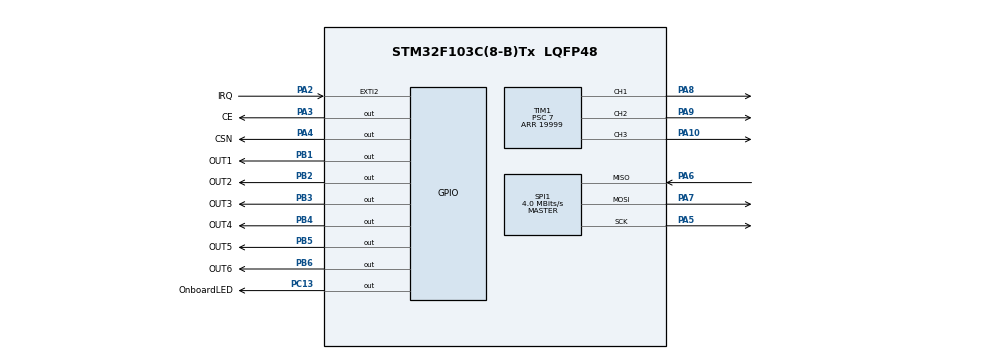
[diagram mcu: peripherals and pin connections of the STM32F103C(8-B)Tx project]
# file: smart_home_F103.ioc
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Mcu.Family=STM32F1
Mcu.Name=STM32F103C(8-B)Tx
Mcu.Package=LQFP48
NVIC.PriorityGroup=NVIC_PRIORITYGROUP_4
PA10.Signal=S_TIM1_CH3
PA13.Mode=Serial_Wire
PA13.Signal=SYS_JTMS-SWDIO
PA14.Mode=Serial_Wire
PA14.Signal=SYS_JTCK-SWCLK
PA2.GPIO_Label=IRQ
PA2.GPIO_ModeDefaultEXTI=GPIO_MODE_IT_FALLING
PA2.Signal=GPXTI2
PA3.GPIO_Label=CE
PA3.Signal=GPIO_Output
PA4.GPIO_Label=CSN
PA4.Signal=GPIO_Output
PA5.Mode=Full_Duplex_Master
PA5.Signal=SPI1_SCK
PA6.Mode=Full_Duplex_Master
PA6.Signal=SPI1_MISO
PA7.Mode=Full_Duplex_Master
PA7.Signal=SPI1_MOSI
PA8.Signal=S_TIM1_CH1
PA9.Signal=S_TIM1_CH2
PB1.GPIO_Label=OUT1
PB1.Signal=GPIO_Output
PB2.GPIO_Label=OUT2
PB2.Signal=GPIO_Output
PB3.GPIO_Label=OUT3
PB3.Signal=GPIO_Output
PB4.GPIO_Label=OUT4
PB4.Signal=GPIO_Output
PB5.GPIO_Label=OUT5
PB5.Signal=GPIO_Output
PB6.GPIO_Label=OUT6
PB6.Signal=GPIO_Output
PC13-TAMPER-RTC.GPIO_Label=OnboardLED
PC13-TAMPER-RTC.Signal=GPIO_Output
ProjectManager.HeapSize=0x200
ProjectManager.StackSize=0x400
ProjectManager.TargetToolchain=STM32CubeIDE
RCC.APB1Freq_Value=8000000
RCC.APB2Freq_Value=8000000
SH.S_TIM1_CH1.0=TIM1_CH1,PWM Generation1 CH1
SH.S_TIM1_CH2.0=TIM1_CH2,PWM Generation2 CH2
SH.S_TIM1_CH3.0=TIM1_CH3,PWM Generation3 CH3
SPI1.CalculateBaudRate=4.0 MBits/s
SPI1.Direction=SPI_DIRECTION_2LINES
SPI1.Mode=SPI_MODE_MASTER
SPI1.VirtualType=VM_MASTER
TIM1.Channel-PWM\ Generation1\ CH1=TIM_CHANNEL_1
TIM1.Channel-PWM\ Generation2\ CH2=TIM_CHANNEL_2
TIM1.Channel-PWM\ Generation3\ CH3=TIM_CHANNEL_3
TIM1.Period=19999
TIM1.Prescaler=7
TIM1.Pulse-PWM\ Generation1\ CH1=1540
TIM1.Pulse-PWM\ Generation2\ CH2=1540
TIM1.Pulse-PWM\ Generation3\ CH3=1540
board=custom

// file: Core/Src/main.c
/* USER CODE BEGIN Header */
/**
  ******************************************************************************
  * @file           : main.c
  * @brief          : Main program body
  ******************************************************************************
  * @attention
  *
  * <h2><center>&copy; Copyright (c) 2021 STMicroelectronics.
  * All rights reserved.</center></h2>
  *
  * This software component is licensed by ST under BSD 3-Clause license,
  * the "License"; You may not use this file except in compliance with the
  * License. You may obtain a copy of the License at:
  *                        opensource.org/licenses/BSD-3-Clause
  *
  ******************************************************************************
  */
/* USER CODE END Header */
#include "main.h"

/* USER CODE BEGIN Includes */
#include <client.h>
/* USER CODE END Includes */

SPI_HandleTypeDef hspi1;

TIM_HandleTypeDef htim1;

void SystemClock_Config(void);
static void MX_GPIO_Init(void);
static void MX_SPI1_Init(void);
static void MX_TIM1_Init(void);

int main(void)
{

  /* MCU Configuration--------------------------------------------------------*/

  /* Reset of all peripherals, Initializes the Flash interface and the Systick. */
  HAL_Init();

  /* Configure the system clock */
  SystemClock_Config();

  /* Initialize all configured peripherals */
  MX_GPIO_Init();
  MX_SPI1_Init();
  MX_TIM1_Init();
  /* USER CODE BEGIN 2 */
  smartHomeGPIOSwitcher(
      &htim1, TIM_CHANNEL_1,
      &htim1, TIM_CHANNEL_2,
      &htim1, TIM_CHANNEL_3
  );
  /* USER CODE END 2 */

  /* Infinite loop */
  while (1)
  {

  }
}

void SystemClock_Config(void)
{
  RCC_OscInitTypeDef RCC_OscInitStruct = {0};
  RCC_ClkInitTypeDef RCC_ClkInitStruct = {0};

  /** Initializes the RCC Oscillators according to the specified parameters
  * in the RCC_OscInitTypeDef structure.
  */
  RCC_OscInitStruct.OscillatorType = RCC_OSCILLATORTYPE_HSI;
  RCC_OscInitStruct.HSIState = RCC_HSI_ON;
  RCC_OscInitStruct.HSICalibrationValue = RCC_HSICALIBRATION_DEFAULT;
  RCC_OscInitStruct.PLL.PLLState = RCC_PLL_NONE;
  if (HAL_RCC_OscConfig(&RCC_OscInitStruct) != HAL_OK)
  {
    Error_Handler();
  }
  /** Initializes the CPU, AHB and APB buses clocks
  */
  RCC_ClkInitStruct.ClockType = RCC_CLOCKTYPE_HCLK|RCC_CLOCKTYPE_SYSCLK
                              |RCC_CLOCKTYPE_PCLK1|RCC_CLOCKTYPE_PCLK2;
  RCC_ClkInitStruct.SYSCLKSource = RCC_SYSCLKSOURCE_HSI;
  RCC_ClkInitStruct.AHBCLKDivider = RCC_SYSCLK_DIV1;
  RCC_ClkInitStruct.APB1CLKDivider = RCC_HCLK_DIV1;
  RCC_ClkInitStruct.APB2CLKDivider = RCC_HCLK_DIV1;

  if (HAL_RCC_ClockConfig(&RCC_ClkInitStruct, FLASH_LATENCY_0) != HAL_OK)
  {
    Error_Handler();
  }
}

static void MX_SPI1_Init(void)
{

  /* SPI1 parameter configuration*/
  hspi1.Instance = SPI1;
  hspi1.Init.Mode = SPI_MODE_MASTER;
  hspi1.Init.Direction = SPI_DIRECTION_2LINES;
  hspi1.Init.DataSize = SPI_DATASIZE_8BIT;
  hspi1.Init.CLKPolarity = SPI_POLARITY_LOW;
  hspi1.Init.CLKPhase = SPI_PHASE_1EDGE;
  hspi1.Init.NSS = SPI_NSS_SOFT;
  hspi1.Init.BaudRatePrescaler = SPI_BAUDRATEPRESCALER_2;
  hspi1.Init.FirstBit = SPI_FIRSTBIT_MSB;
  hspi1.Init.TIMode = SPI_TIMODE_DISABLE;
  hspi1.Init.CRCCalculation = SPI_CRCCALCULATION_DISABLE;
  hspi1.Init.CRCPolynomial = 10;
  if (HAL_SPI_Init(&hspi1) != HAL_OK)
  {
    Error_Handler();
  }

}

static void MX_TIM1_Init(void)
{

  TIM_MasterConfigTypeDef sMasterConfig = {0};
  TIM_OC_InitTypeDef sConfigOC = {0};
  TIM_BreakDeadTimeConfigTypeDef sBreakDeadTimeConfig = {0};

  htim1.Instance = TIM1;
  htim1.Init.Prescaler = 7;
  htim1.Init.CounterMode = TIM_COUNTERMODE_UP;
  htim1.Init.Period = 19999;
  htim1.Init.ClockDivision = TIM_CLOCKDIVISION_DIV1;
  htim1.Init.RepetitionCounter = 0;
  htim1.Init.AutoReloadPreload = TIM_AUTORELOAD_PRELOAD_DISABLE;
  if (HAL_TIM_PWM_Init(&htim1) != HAL_OK)
  {
    Error_Handler();
  }
  sMasterConfig.MasterOutputTrigger = TIM_TRGO_RESET;
  sMasterConfig.MasterSlaveMode = TIM_MASTERSLAVEMODE_DISABLE;
  if (HAL_TIMEx_MasterConfigSynchronization(&htim1, &sMasterConfig) != HAL_OK)
  {
    Error_Handler();
  }
  sConfigOC.OCMode = TIM_OCMODE_PWM1;
  sConfigOC.Pulse = 1540;
  sConfigOC.OCPolarity = TIM_OCPOLARITY_HIGH;
  sConfigOC.OCNPolarity = TIM_OCNPOLARITY_HIGH;
  sConfigOC.OCFastMode = TIM_OCFAST_DISABLE;
  sConfigOC.OCIdleState = TIM_OCIDLESTATE_RESET;
  sConfigOC.OCNIdleState = TIM_OCNIDLESTATE_RESET;
  if (HAL_TIM_PWM_ConfigChannel(&htim1, &sConfigOC, TIM_CHANNEL_1) != HAL_OK)
  {
    Error_Handler();
  }
  if (HAL_TIM_PWM_ConfigChannel(&htim1, &sConfigOC, TIM_CHANNEL_2) != HAL_OK)
  {
    Error_Handler();
  }
  if (HAL_TIM_PWM_ConfigChannel(&htim1, &sConfigOC, TIM_CHANNEL_3) != HAL_OK)
  {
    Error_Handler();
  }
  sBreakDeadTimeConfig.OffStateRunMode = TIM_OSSR_DISABLE;
  sBreakDeadTimeConfig.OffStateIDLEMode = TIM_OSSI_DISABLE;
  sBreakDeadTimeConfig.LockLevel = TIM_LOCKLEVEL_OFF;
  sBreakDeadTimeConfig.DeadTime = 0;
  sBreakDeadTimeConfig.BreakState = TIM_BREAK_DISABLE;
  sBreakDeadTimeConfig.BreakPolarity = TIM_BREAKPOLARITY_HIGH;
  sBreakDeadTimeConfig.AutomaticOutput = TIM_AUTOMATICOUTPUT_DISABLE;
  if (HAL_TIMEx_ConfigBreakDeadTime(&htim1, &sBreakDeadTimeConfig) != HAL_OK)
  {
    Error_Handler();
  }
  HAL_TIM_MspPostInit(&htim1);

}

static void MX_GPIO_Init(void)
{
  GPIO_InitTypeDef GPIO_InitStruct = {0};

  /* GPIO Ports Clock Enable */
  __HAL_RCC_GPIOC_CLK_ENABLE();
  __HAL_RCC_GPIOA_CLK_ENABLE();
  __HAL_RCC_GPIOB_CLK_ENABLE();

  /*Configure GPIO pin Output Level */
  HAL_GPIO_WritePin(OnboardLED_GPIO_Port, OnboardLED_Pin, GPIO_PIN_RESET);

  /*Configure GPIO pin Output Level */
  HAL_GPIO_WritePin(GPIOA, CE_Pin|CSN_Pin, GPIO_PIN_RESET);

  /*Configure GPIO pin Output Level */
  HAL_GPIO_WritePin(GPIOB, OUT1_Pin|OUT2_Pin|OUT3_Pin|OUT4_Pin
                          |OUT5_Pin|OUT6_Pin, GPIO_PIN_RESET);

  /*Configure GPIO pin : OnboardLED_Pin */
  GPIO_InitStruct.Pin = OnboardLED_Pin;
  GPIO_InitStruct.Mode = GPIO_MODE_OUTPUT_PP;
  GPIO_InitStruct.Pull = GPIO_NOPULL;
  GPIO_InitStruct.Speed = GPIO_SPEED_FREQ_LOW;
  HAL_GPIO_Init(OnboardLED_GPIO_Port, &GPIO_InitStruct);

  /*Configure GPIO pin : IRQ_Pin */
  GPIO_InitStruct.Pin = IRQ_Pin;
  GPIO_InitStruct.Mode = GPIO_MODE_IT_FALLING;
  GPIO_InitStruct.Pull = GPIO_NOPULL;
  HAL_GPIO_Init(IRQ_GPIO_Port, &GPIO_InitStruct);

  /*Configure GPIO pins : CE_Pin CSN_Pin */
  GPIO_InitStruct.Pin = CE_Pin|CSN_Pin;
  GPIO_InitStruct.Mode = GPIO_MODE_OUTPUT_PP;
  GPIO_InitStruct.Pull = GPIO_NOPULL;
  GPIO_InitStruct.Speed = GPIO_SPEED_FREQ_LOW;
  HAL_GPIO_Init(GPIOA, &GPIO_InitStruct);

  /*Configure GPIO pins : OUT1_Pin OUT2_Pin OUT3_Pin OUT4_Pin
                           OUT5_Pin OUT6_Pin */
  GPIO_InitStruct.Pin = OUT1_Pin|OUT2_Pin|OUT3_Pin|OUT4_Pin
                          |OUT5_Pin|OUT6_Pin;
  GPIO_InitStruct.Mode = GPIO_MODE_OUTPUT_PP;
  GPIO_InitStruct.Pull = GPIO_NOPULL;
  GPIO_InitStruct.Speed = GPIO_SPEED_FREQ_LOW;
  HAL_GPIO_Init(GPIOB, &GPIO_InitStruct);

}

void Error_Handler(void)
{
  __disable_irq();
  while (1)
  {
  }
}

/************************ (C) COPYRIGHT STMicroelectronics *****END OF FILE****/
